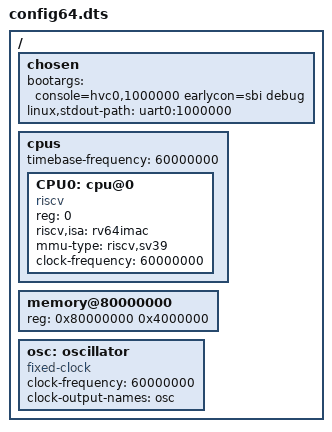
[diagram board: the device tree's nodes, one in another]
// SPDX-License-Identifier: GPL-2.0
/dts-v1/;

/ {
  #address-cells = <1>;
  #size-cells = <1>;

    chosen {
        bootargs = "console=hvc0,1000000 earlycon=sbi debug";
        linux,stdout-path = "uart0:1000000";
    };    

  cpus {
    #address-cells = <1>;
    #size-cells = <0>;
    timebase-frequency = <60000000>;
    CPU0: cpu@0 {
      device_type = "cpu";
      reg = <0>;
      status = "okay";
      compatible = "riscv";
      riscv,isa = "rv64imac";
      mmu-type = "riscv,sv39";
      clock-frequency = <60000000>;
    };
  };

  memory@80000000 {
      device_type = "memory";
      reg = <0x80000000 0x4000000>;
  };

  osc: oscillator {
      compatible = "fixed-clock";
      #clock-cells = <0>;
      clock-frequency  = <60000000>;
      clock-output-names = "osc";
  };
};
